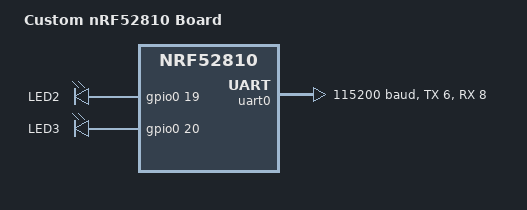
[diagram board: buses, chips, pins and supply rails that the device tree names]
/dts-v1/;
#include <nordic/nrf52810_qfaa.dtsi>
#include <dt-bindings/gpio/gpio.h>
/ {
	model = "Custom nRF52810 Board";
	compatible = "custom,nrf52810-board";

	chosen {
		zephyr,console = &uart0;
		zephyr,shell-uart = &uart0;
	};

	leds {
		compatible = "gpio-leds";

		led2: led_2 {
			gpios = <&gpio0 19 GPIO_ACTIVE_HIGH>;
			label = "LED2";
		};

		led3: led_3 {
			gpios = <&gpio0 20 GPIO_ACTIVE_HIGH>;
			label = "LED3";
		};
	};

	aliases {
		led0 = &led2;
		led1 = &led3;
	};
};

&gpio0 {
	status = "okay";
};

&uart0 {
	status = "okay";
	current-speed = <115200>;
	tx-pin = <6>;
	rx-pin = <8>;
};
